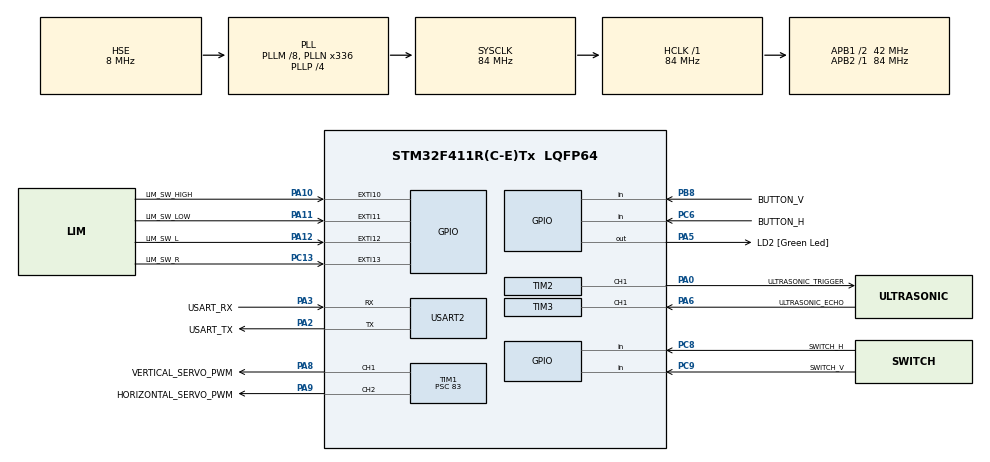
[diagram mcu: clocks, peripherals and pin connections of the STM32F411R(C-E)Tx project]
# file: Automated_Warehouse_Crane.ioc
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FREERTOS.Tasks01=defaultTask,24,128,StartDefaultTask,Default,NULL,Dynamic,NULL,NULL
Mcu.Family=STM32F4
Mcu.Name=STM32F411R(C-E)Tx
Mcu.Package=LQFP64
NVIC.EXTI15_10_IRQn=true\:5\:0\:false\:false\:true\:true\:true\:true\:true
NVIC.PriorityGroup=NVIC_PRIORITYGROUP_4
NVIC.TIM1_BRK_TIM9_IRQn=true\:15\:0\:false\:false\:true\:false\:false\:true\:true
NVIC.TIM1_UP_TIM10_IRQn=true\:5\:0\:false\:false\:true\:true\:true\:true\:true
NVIC.TIM3_IRQn=true\:5\:0\:false\:false\:true\:true\:true\:true\:true
NVIC.USART2_IRQn=true\:5\:0\:false\:false\:true\:true\:true\:true\:true
PA0-WKUP.GPIO_Label=ULTRASONIC_TRIGGER
PA0-WKUP.GPIO_PuPd=GPIO_NOPULL
PA0-WKUP.Signal=S_TIM2_CH1_ETR
PA10.GPIO_Label=LIM_SW_HIGH
PA10.GPIO_ModeDefaultEXTI=GPIO_MODE_IT_FALLING
PA10.GPIO_PuPd=GPIO_PULLUP
PA10.Signal=GPXTI10
PA11.GPIO_Label=LIM_SW_LOW
PA11.GPIO_ModeDefaultEXTI=GPIO_MODE_IT_FALLING
PA11.GPIO_PuPd=GPIO_PULLUP
PA11.Signal=GPXTI11
PA12.GPIO_Label=LIM_SW_L
PA12.GPIO_ModeDefaultEXTI=GPIO_MODE_IT_FALLING
PA12.GPIO_PuPd=GPIO_PULLUP
PA12.Signal=GPXTI12
PA13.GPIO_Label=TMS
PA13.Mode=Serial_Wire
PA13.Signal=SYS_JTMS-SWDIO
PA14.GPIO_Label=TCK
PA14.Mode=Serial_Wire
PA14.Signal=SYS_JTCK-SWCLK
PA2.GPIO_Label=USART_TX
PA2.Mode=Asynchronous
PA2.Signal=USART2_TX
PA3.GPIO_Label=USART_RX
PA3.Mode=Asynchronous
PA3.Signal=USART2_RX
PA5.GPIO_Label=LD2 [Green Led]
PA5.Signal=GPIO_Output
PA6.GPIO_Label=ULTRASONIC_ECHO
PA6.Signal=S_TIM3_CH1
PA8.GPIO_Label=VERTICAL_SERVO_PWM
PA8.Signal=S_TIM1_CH1
PA9.GPIO_Label=HORIZONTAL_SERVO_PWM
PA9.Signal=S_TIM1_CH2
PB3.GPIO_Label=SWO
PB3.Signal=SYS_JTDO-SWO
PB8.GPIO_Label=BUTTON_V
PB8.GPIO_PuPd=GPIO_PULLUP
PB8.Signal=GPIO_Input
PC13-ANTI_TAMP.GPIO_Label=LIM_SW_R
PC13-ANTI_TAMP.GPIO_ModeDefaultEXTI=GPIO_MODE_IT_FALLING
PC13-ANTI_TAMP.GPIO_PuPd=GPIO_PULLUP
PC13-ANTI_TAMP.Signal=GPXTI13
PC14-OSC32_IN.Mode=LSE-External-Oscillator
PC14-OSC32_IN.Signal=RCC_OSC32_IN
PC15-OSC32_OUT.Mode=LSE-External-Oscillator
PC15-OSC32_OUT.Signal=RCC_OSC32_OUT
PC6.GPIO_Label=BUTTON_H
PC6.GPIO_PuPd=GPIO_PULLUP
PC6.Signal=GPIO_Input
PC8.GPIO_Label=SWITCH_H
PC8.GPIO_PuPd=GPIO_PULLUP
PC8.Signal=GPIO_Input
PC9.GPIO_Label=SWITCH_V
PC9.GPIO_PuPd=GPIO_PULLUP
PC9.Signal=GPIO_Input
PH0\ -\ OSC_IN.Mode=HSE-External-Clock-Source
PH0\ -\ OSC_IN.Signal=RCC_OSC_IN
PH1\ -\ OSC_OUT.Mode=HSE-External-Clock-Source
PH1\ -\ OSC_OUT.Signal=RCC_OSC_OUT
ProjectManager.HeapSize=0x200
ProjectManager.StackSize=0x400
ProjectManager.TargetToolchain=CMake
RCC.48MHZClocksFreq_Value=84000000
RCC.AHBFreq_Value=84000000
RCC.APB1CLKDivider=RCC_HCLK_DIV2
RCC.APB1Freq_Value=42000000
RCC.APB1TimFreq_Value=84000000
RCC.APB2Freq_Value=84000000
RCC.APB2TimFreq_Value=84000000
RCC.CortexFreq_Value=84000000
RCC.FLatency-AdvancedSettings=FLASH_LATENCY_2
RCC.HCLKFreq_Value=84000000
RCC.HSE_VALUE=8000000
RCC.HSI_VALUE=16000000
RCC.PLLM=8
RCC.PLLN=336
RCC.PLLP=RCC_PLLP_DIV4
RCC.PLLSourceVirtual=RCC_PLLSOURCE_HSE
RCC.SYSCLKFreq_VALUE=84000000
RCC.SYSCLKSource=RCC_SYSCLKSOURCE_PLLCLK
RCC.VCOOutputFreq_Value=336000000
SH.S_TIM1_CH1.0=TIM1_CH1,PWM Generation1 CH1
SH.S_TIM1_CH2.0=TIM1_CH2,PWM Generation2 CH2
SH.S_TIM2_CH1_ETR.0=TIM2_CH1,PWM Generation1 CH1
SH.S_TIM3_CH1.0=TIM3_CH1,PWM_Input_1
TIM1.Channel-PWM\ Generation1\ CH1=TIM_CHANNEL_1
TIM1.Channel-PWM\ Generation2\ CH2=TIM_CHANNEL_2
TIM1.OCMode_PWM-PWM\ Generation1\ CH1=TIM_OCMODE_PWM1
TIM1.Period=19999
TIM1.Prescaler=83
TIM2.Channel-PWM\ Generation1\ CH1=TIM_CHANNEL_1
TIM2.OCPolarity_1=TIM_OCPOLARITY_LOW
TIM2.Period=1024
TIM2.Pulse-PWM\ Generation1\ CH1=184
TIM2.TIM_MasterOutputTrigger=TIM_TRGO_RESET
TIM3.Prescaler=83
USART2.VirtualMode=VM_ASYNC
VP_FREERTOS_VS_CMSIS_V2.Mode=CMSIS_V2
VP_TIM2_VS_OPM.Mode=OPM_bit
board=NUCLEO-F411RE

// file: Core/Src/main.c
/* USER CODE BEGIN Header */
/**
 ******************************************************************************
 * @file           : main.c
 * @brief          : Main program body
 ******************************************************************************
 * @attention
 *
 * Copyright (c) 2025 STMicroelectronics.
 * All rights reserved.
 *
 * This software is licensed under terms that can be found in the LICENSE file
 * in the root directory of this software component.
 * If no LICENSE file comes with this software, it is provided AS-IS.
 *
 ******************************************************************************
 */
/* USER CODE END Header */
#include "main.h"
#include "cmsis_os.h"
#include "tim.h"
#include "usart.h"
#include "gpio.h"

/* USER CODE BEGIN Includes */
#include "user_main.h"
/* USER CODE END Includes */

void SystemClock_Config(void);
void MX_FREERTOS_Init(void);

int main(void)
{

  /* MCU Configuration--------------------------------------------------------*/

  /* Reset of all peripherals, Initializes the Flash interface and the Systick. */
  HAL_Init();

  /* Configure the system clock */
  SystemClock_Config();

  /* Initialize all configured peripherals */
  MX_GPIO_Init();
  MX_USART2_UART_Init();
  MX_TIM1_Init();
  MX_TIM2_Init();
  MX_TIM3_Init();
  /* USER CODE BEGIN 2 */
  user_main();
#if 0 /* Comment out scheduler init */
  /* USER CODE END 2 */

  /* Init scheduler */
  osKernelInitialize();  /* Call init function for freertos objects (in cmsis_os2.c) */
  MX_FREERTOS_Init();

  /* Start scheduler */
  osKernelStart();

  /* We should never get here as control is now taken by the scheduler */

  /* Infinite loop */
  /* USER CODE BEGIN WHILE */
#endif
  while (1)
  {
    /* USER CODE END WHILE */

  }
}

void SystemClock_Config(void)
{
  RCC_OscInitTypeDef RCC_OscInitStruct = {0};
  RCC_ClkInitTypeDef RCC_ClkInitStruct = {0};

  /** Configure the main internal regulator output voltage
  */
  __HAL_RCC_PWR_CLK_ENABLE();
  __HAL_PWR_VOLTAGESCALING_CONFIG(PWR_REGULATOR_VOLTAGE_SCALE1);

  /** Initializes the RCC Oscillators according to the specified parameters
  * in the RCC_OscInitTypeDef structure.
  */
  RCC_OscInitStruct.OscillatorType = RCC_OSCILLATORTYPE_HSE;
  RCC_OscInitStruct.HSEState = RCC_HSE_BYPASS;
  RCC_OscInitStruct.PLL.PLLState = RCC_PLL_ON;
  RCC_OscInitStruct.PLL.PLLSource = RCC_PLLSOURCE_HSE;
  RCC_OscInitStruct.PLL.PLLM = 8;
  RCC_OscInitStruct.PLL.PLLN = 336;
  RCC_OscInitStruct.PLL.PLLP = RCC_PLLP_DIV4;
  RCC_OscInitStruct.PLL.PLLQ = 4;
  if (HAL_RCC_OscConfig(&RCC_OscInitStruct) != HAL_OK)
  {
    Error_Handler();
  }

  /** Initializes the CPU, AHB and APB buses clocks
  */
  RCC_ClkInitStruct.ClockType = RCC_CLOCKTYPE_HCLK|RCC_CLOCKTYPE_SYSCLK
                              |RCC_CLOCKTYPE_PCLK1|RCC_CLOCKTYPE_PCLK2;
  RCC_ClkInitStruct.SYSCLKSource = RCC_SYSCLKSOURCE_PLLCLK;
  RCC_ClkInitStruct.AHBCLKDivider = RCC_SYSCLK_DIV1;
  RCC_ClkInitStruct.APB1CLKDivider = RCC_HCLK_DIV2;
  RCC_ClkInitStruct.APB2CLKDivider = RCC_HCLK_DIV1;

  if (HAL_RCC_ClockConfig(&RCC_ClkInitStruct, FLASH_LATENCY_2) != HAL_OK)
  {
    Error_Handler();
  }
}

void Error_Handler(void)
{
  __disable_irq();
  while (1)
  {
  }
}

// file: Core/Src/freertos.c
/* USER CODE BEGIN Header */
/**
 ******************************************************************************
 * File Name          : freertos.c
 * Description        : Code for freertos applications
 ******************************************************************************
 * @attention
 *
 * Copyright (c) 2025 STMicroelectronics.
 * All rights reserved.
 *
 * This software is licensed under terms that can be found in the LICENSE file
 * in the root directory of this software component.
 * If no LICENSE file comes with this software, it is provided AS-IS.
 *
 ******************************************************************************
 */
/* USER CODE END Header */

#include "FreeRTOS.h"
#include "task.h"
#include "main.h"
#include "cmsis_os.h"

/* Definitions for defaultTask */
osThreadId_t defaultTaskHandle;
const osThreadAttr_t defaultTask_attributes = {
  .name = "defaultTask",
  .stack_size = 128 * 4,
  .priority = (osPriority_t) osPriorityNormal,
};

void StartDefaultTask(void *argument);

void MX_FREERTOS_Init(void); /* (MISRA C 2004 rule 8.1) */

void MX_FREERTOS_Init(void) {

  /* Create the thread(s) */
  /* creation of defaultTask */
  defaultTaskHandle = osThreadNew(StartDefaultTask, NULL, &defaultTask_attributes);

}

void StartDefaultTask(void *argument)
{
  for (;;)
  {
    osDelay(1);
  }
}
